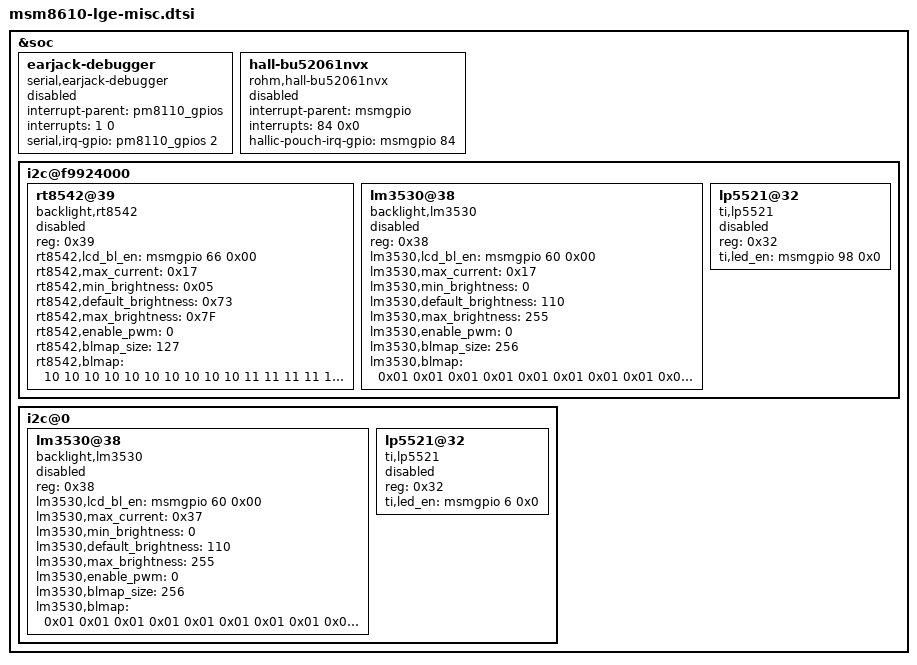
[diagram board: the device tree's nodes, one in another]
/* Copyright (c) 2012, Code Aurora Forum. All rights reserved.
 *
 * This program is free software; you can redistribute it and/or modify
 * it under the terms of the GNU General Public License version 2 and
 * only version 2 as published by the Free Software Foundation.
 *
 * This program is distributed in the hope that it will be useful,
 * but WITHOUT ANY WARRANTY; without even the implied warranty of
 * MERCHANTABILITY or FITNESS FOR A PARTICULAR PURPOSE.  See the
 * GNU General Public License for more details.
 */

&soc {
	earjack-debugger {
		compatible = "serial,earjack-debugger";
		status = "disable";
		interrupt-parent = <&pm8110_gpios>;
		interrupts = <1 0>;
		serial,irq-gpio = <&pm8110_gpios 2 0x0>;
	};

    hall-bu52061nvx {
        compatible = "rohm,hall-bu52061nvx";
        interrupt-parent = <&msmgpio>;
        interrupts = <84 0x0>;
        hallic-pouch-irq-gpio = <&msmgpio 84 0x00>;
        status = "disable";
    };
	i2c@f9924000 {
		rt8542@39 {
			compatible = "backlight,rt8542";
			status = "disable";
			reg = <0x39>;
			rt8542,lcd_bl_en = <&msmgpio 66 0x00>;
			rt8542,max_current = <0x17>;
			rt8542,min_brightness = <0x05>;
			rt8542,default_brightness = <0x73>;
			rt8542,max_brightness = <0x7F>;
			rt8542,enable_pwm = <0>;
			rt8542,blmap_size = <127>;
			rt8542,blmap = <
				10 10 10 10 10 10 10 10 10 10
				11 11 11 11 11 11 12 12 12 12
				13 13 13 14 14 15 15 15 16 16
				17 17 18 19 19 20 20 21 22 23
				23 24 25 26 26 27 28 29 30 31
				32 33 34 35 36 37 38 39 41 42
				43 44 45 47 48 49 51 52 54 55
				57 58 60 61 63 64 66 68 69 71
				73 75 77 78 80 82 84 86 88 90
				92 94 96 98 100 103 105 107 109 112
				114 115 116 117 118 119 120 121 122 122
				122 122 122 123 123 123 123 124 124 124
				124 126 126 126 126 127 127>;
		};
		lm3530@38 {
			compatible = "backlight,lm3530";
			status = "disable";
			reg = <0x38>;
			lm3530,lcd_bl_en = <&msmgpio 60 0x00>;
			lm3530,max_current = <0x17>;
			lm3530,min_brightness = <0>;
			lm3530,default_brightness = <110>;
			lm3530,max_brightness = <255>;
			lm3530,enable_pwm = <0>;
			lm3530,blmap_size = <256>;
			lm3530,blmap = <
				0x01 0x01 0x01 0x01 0x01 0x01 0x01 0x01 0x01 0x01 /*09*/
				0x01 0x01 0x01 0x01 0x01 0x01 0x01 0x01 0x01 0x01 /*19*/
				0x01 0x01 0x01 0x01 0x01 0x01 0x02 0x02 0x02 0x02 /*29*/
				0x02 0x02 0x02 0x02 0x02 0x02 0x02 0x02 0x02 0x03 /*39*/
				0x03 0x03 0x03 0x03 0x03 0x03 0x03 0x03 0x03 0x03 /*49*/
				0x03 0x03 0x04 0x04 0x04 0x04 0x04 0x04 0x04 0x04 /*59*/
				0x04 0x04 0x04 0x05 0x05 0x05 0x05 0x05 0x06 0x06 /*69*/
				0x06 0x06 0x06 0x06 0x06 0x07 0x07 0x07 0x07 0x07 /*79*/
				0x08 0x08 0x08 0x08 0x08 0x08 0x08 0x08 0x09 0x09 /*89*/
				0x09 0x09 0x0A 0x0A 0x0A 0x0A 0x0B 0x0B 0x0B 0x0B /*99*/
				0x0B 0x0C 0x0C 0x0C 0x0C 0x0D 0x0D 0x0D 0x0D 0x0E /*109*/
				0x0E 0x0E 0x0E 0x0F 0x0F 0x0F 0x10 0x10 0x11 0x11 /*119*/
				0x12 0x12 0x12 0x12 0x13 0x13 0x13 0x13 0x14 0x14 /*129*/
				0x14 0x15 0x15 0x15 0x15 0x15 0x16 0x16 0x17 0x17 /*139*/
				0x17 0x18 0x18 0x18 0x19 0x19 0x19 0x19 0x19 0x1A /*149*/
				0x1A 0x1B 0x1B 0x1C 0x1D 0x1D 0x1E 0x1E 0x1E 0x1E /*159*/
				0x1E 0x1F 0x1F 0x20 0x21 0x21 0x22 0x22 0x23 0x23 /*169*/
				0x24 0x24 0x24 0x24 0x25 0x25 0x26 0x27 0x28 0x29 /*179*/
				0x2A 0x2A 0x2B 0x2B 0x2B 0x2B 0x2C 0x2D 0x2E 0x2F /*189*/
				0x30 0x31 0x32 0x33 0x33 0x33 0x33 0x34 0x34 0x35 /*199*/
				0x36 0x37 0x38 0x39 0x3A 0x3B 0x3B 0x3B 0x3B 0x3C /*209*/
				0x3C 0x3D 0x3E 0x3E 0x3F 0x40 0x41 0x42 0x42 0x43 /*219*/
				0x43 0x43 0x43 0x44 0x44 0x46 0x48 0x49 0x4A 0x4C /*229*/
				0x4D 0x4E 0x4E 0x4E 0x4E 0x4F 0x50 0x52 0x53 0x55 /*239*/
				0x56 0x57 0x58 0x58 0x58 0x58 0x59 0x5A 0x5B 0x5C /*249*/
				0x5E 0x5F 0x60 0x61 0x62 0x63 /*255*/>;
        	};
		lp5521@32 {
			compatible = "ti,lp5521";
			status = "disable";
			reg = <0x32>;
			ti,led_en = <&msmgpio 98 0x0>;
		};
	};
	i2c@0 {
		lm3530@38 {
			compatible = "backlight,lm3530";
			status = "disable";
			reg = <0x38>;
			lm3530,lcd_bl_en = <&msmgpio 60 0x00>;
			lm3530,max_current = <0x37>;
			lm3530,min_brightness = <0>;
			lm3530,default_brightness = <110>;
			lm3530,max_brightness = <255>;
			lm3530,enable_pwm = <0>;
			lm3530,blmap_size = <256>;
			lm3530,blmap = <
				0x01 0x01 0x01 0x01 0x01 0x01 0x01 0x01 0x01 0x01 /*09*/
				0x01 0x01 0x01 0x01 0x01 0x01 0x01 0x01 0x01 0x01 /*19*/
				0x01 0x01 0x01 0x01 0x01 0x01 0x02 0x02 0x02 0x02 /*29*/
				0x02 0x02 0x02 0x02 0x02 0x02 0x02 0x02 0x02 0x03 /*39*/
				0x03 0x03 0x03 0x03 0x03 0x03 0x03 0x03 0x03 0x03 /*49*/
				0x03 0x03 0x04 0x04 0x04 0x04 0x04 0x04 0x04 0x05 /*59*/
				0x05 0x05 0x05 0x05 0x05 0x05 0x05 0x06 0x06 0x06 /*69*/
				0x06 0x07 0x07 0x07 0x07 0x08 0x08 0x08 0x08 0x09 /*79*/
				0x09 0x09 0x09 0x0A 0x0A 0x0A 0x0B 0x0B 0x0B 0x0B /*89*/
				0x0B 0x0C 0x0C 0x0C 0x0C 0x0C 0x0D 0x0D 0x0D 0x0E /*99*/
				0x0E 0x0F 0x0F 0x10 0x10 0x10 0x11 0x11 0x12 0x12 /*109*/
				0x12 0x12 0x13 0x13 0x13 0x14 0x14 0x15 0x15 0x15 /*119*/
				0x16 0x16 0x16 0x17 0x17 0x18 0x18 0x19 0x19 0x1A /*129*/
				0x1B 0x1B 0x1C 0x1C 0x1C 0x1D 0x1D 0x1E 0x1E 0x1F /*139*/
				0x1F 0x20 0x20 0x21 0x21 0x22 0x22 0x22 0x23 0x23 /*149*/
				0x24 0x25 0x26 0x26 0x27 0x27 0x28 0x29 0x29 0x29 /*159*/
				0x2A 0x2A 0x2B 0x2C 0x2C 0x2D 0x2E 0x2E 0x2F 0x2F /*169*/
				0x30 0x30 0x30 0x31 0x31 0x32 0x32 0x33 0x34 0x35 /*179*/
				0x36 0x37 0x38 0x38 0x38 0x3A 0x3B 0x3C 0x3D 0x3E /*189*/
				0x3E 0x3F 0x40 0x41 0x41 0x41 0x42 0x43 0x43 0x44 /*199*/
				0x45 0x46 0x47 0x48 0x49 0x4B 0x4B 0x4B 0x4C 0x4D /*209*/
				0x4D 0x4E 0x4F 0x50 0x51 0x52 0x53 0x54 0x55 0x56 /*219*/
				0x56 0x56 0x58 0x59 0x5A 0x5B 0x5C 0x5D 0x5E 0x60 /*229*/
				0x62 0x63 0x63 0x63 0x64 0x65 0x66 0x68 0x6A 0x6B /*239*/
				0x6D 0x6F 0x70 0x70 0x70 0x71 0x73 0x75 0x76 0x77 /*249*/
				0x78 0x7A 0x7C 0x7D 0x7E 0x7F /*255*/>;
        };
        /* moved to msm8610-w5ds-camera.dtsi 2013-10-15 yt.jeon@lge.com
		rt8542@39 {
			compatible = "backlight,rt8542";
			status = "ok";
			reg = <0x39>;
			rt8542,lcd_bl_en = <&msmgpio 60 0x00>;
			rt8542,max_current = <0x17>;
			rt8542,min_brightness = <0x05>;
			rt8542,default_brightness = <0x73>;
			rt8542,max_brightness = <0x7F>;
			rt8542,enable_pwm = <0>;
			rt8542,blmap_size = <127>;
			rt8542,blmap = <
				10 10 10 10 10 10 10 10 10 10
				11 11 11 11 11 11 12 12 12 12
				13 13 13 14 14 15 15 15 16 16
				17 17 18 19 19 20 20 21 22 23
				23 24 25 26 26 27 28 29 30 31
				32 33 34 35 36 37 38 39 41 42
				43 44 45 47 48 49 51 52 54 55
				57 58 60 61 63 64 66 68 69 71
				73 75 77 78 80 82 84 86 88 90
				92 94 96 98 100 103 105 107 109 112
				114 115 116 117 118 119 120 121 122 122
				122 122 122 123 123 123 123 124 124 124
				124 126 126 126 126 127 127>;
		};
	*/
		lp5521@32 {
			compatible = "ti,lp5521";
			status = "disable";
			reg = <0x32>;
			ti,led_en = <&msmgpio 6 0x0>;
		};
	};
};
